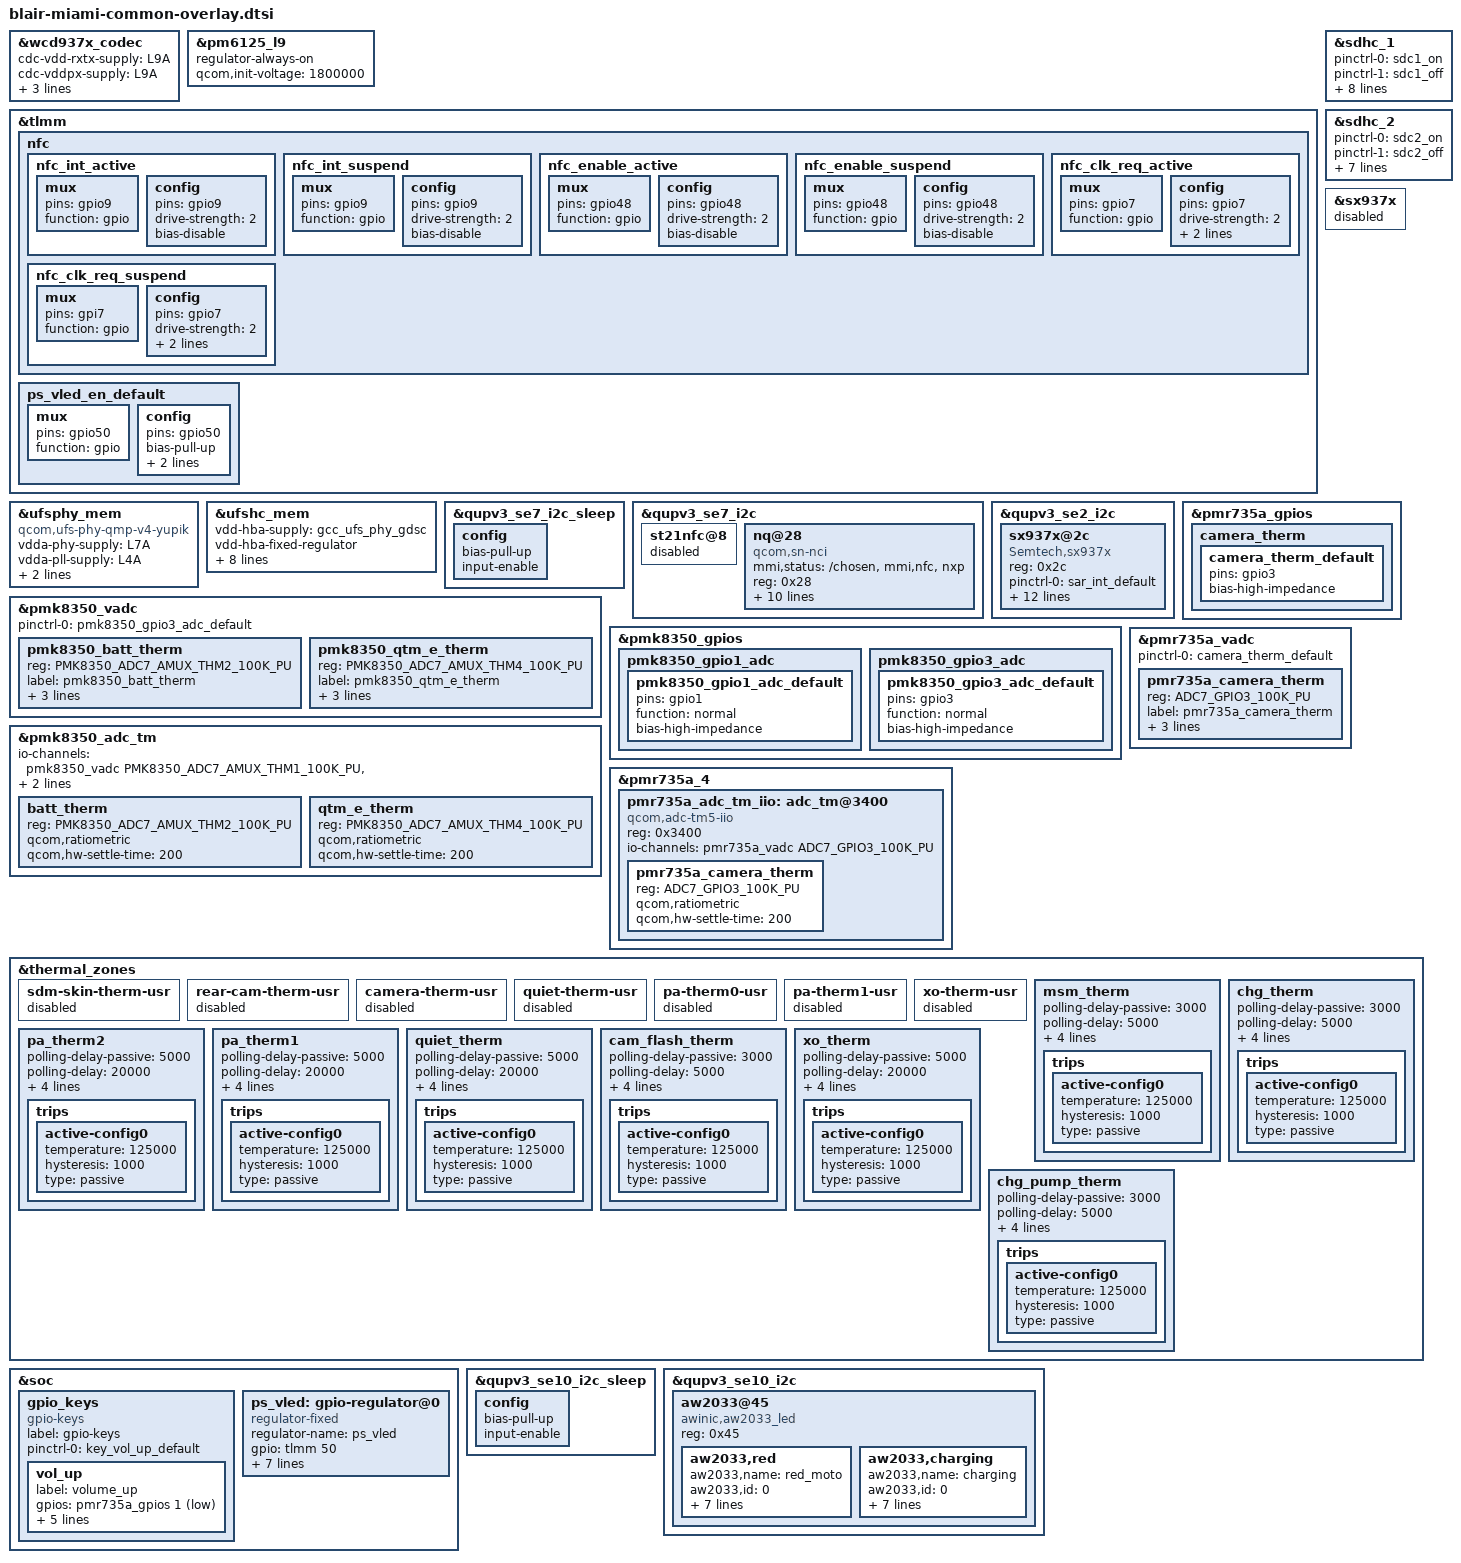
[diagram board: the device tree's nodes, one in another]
/* Copyright (c) 2021, The Linux Foundation. All rights reserved.
 *
 * This program is free software; you can redistribute it and/or modify
 * it under the terms of the GNU General Public License version 2 and
 * only version 2 as published by the Free Software Foundation.
 *
 * This program is distributed in the hope that it will be useful,
 * but WITHOUT ANY WARRANTY; without even the implied warranty of
 * MERCHANTABILITY or FITNESS FOR A PARTICULAR PURPOSE.  See the
 * GNU General Public License for more details.
 */
#include "blair-nopmi-moto-common-overlay.dtsi"

#include <dt-bindings/gpio/gpio.h>
#include <dt-bindings/input/linux-event-codes.h>
#include "holi-pmic-overlay-pm6125.dtsi"
#include "holi-thermal-overlay-pm6125.dtsi"
#include "display/holi-sde-display-mtp-pm6125.dtsi"
#include "display/blair-sde-display-mtp.dtsi"
#include "miami-fps-overlay.dtsi"
#include "miami-display.dtsi"
#include "miami-touchscreen.dtsi"
#include "camera/blair-camera-sensor-mot-miami-overlay.dtsi"
#include "miami-wl2864c.dtsi"
#include "tcpc_config.dtsi"
#include "discrete_charging_miami.dtsi"
#include "discrete-rt-pd-manger.dtsi"
#include "blair-miami-audio-overlay.dtsi"
#include "moto_therm_sys_temp.dtsi"

&wcd937x_codec {
	cdc-vdd-rxtx-supply = <&L9A>;
	cdc-vddpx-supply = <&L9A>;
	qcom,cdc-static-supplies = "cdc-vdd-rxtx",
				   "cdc-vddpx";
	/*
	 * Overriding cdc-vdd-mic-bias-supply to dummy value
	 * to avoid compilation errors as BOB is not definied
	 * for pm6125
	 */
	cdc-vdd-mic-bias-supply = <>;
};

&pm6125_l9 {
		regulator-always-on; //SAR interrupt power
		qcom,init-voltage = <1800000>;
};

&tlmm {
	nfc {
		nfc_int_active: nfc_int_active {
			/* active state */
			mux {
				/* GPIO 9: NFC Read Interrupt */
				pins = "gpio9";
				function = "gpio";
			};

			config {
				pins = "gpio9";
				drive-strength = <2>; /* 2 MA */
				bias-disable;
			};
		};

		nfc_int_suspend: nfc_int_suspend {
			/* sleep state */
			mux {
				/* GPIO 9: NFC Read Interrupt */
				pins = "gpio9";
				function = "gpio";
			};

			config {
				pins = "gpio9";
				drive-strength = <2>; /* 2 MA */
				bias-disable;
			};
		};

		nfc_enable_active: nfc_enable_active {
			mux {
				pins = "gpio48";
				function = "gpio";
			};

			config {
				pins = "gpio48";
				drive-strength = <2>; /* 2 MA */
				bias-disable;
			};
		};

		nfc_enable_suspend: nfc_enable_suspend {
			mux {
				pins = "gpio48";
				function = "gpio";
			};

			config {
				pins = "gpio48";
				drive-strength = <2>; /* 2 MA */
				bias-disable;
			};
		};


		nfc_clk_req_active: nfc_clk_req_active {
			/* active state */
			mux {
				/* GPIO 7: NFC CLK Req*/
				pins = "gpio7";
				function = "gpio";
			};

			config {
				pins = "gpio7";
				drive-strength = <2>; /* 2 MA */
				bias-disable;
				input-enable;
			};
		};

		nfc_clk_req_suspend: nfc_clk_req_suspend {
			/* sleep state */
			mux {
				/* GPIO 7: NFC CLK Req */
				pins = "gpi7";
				function = "gpio";
			};

			config {
				pins = "gpio7";
				drive-strength = <2>; /* 2 MA */
				bias-disable;
				input-enable;
			};
		};
	};
};

/* Dummy LDO reference */
&sdhc_1 {
	status = "ok";

	pinctrl-names = "default", "sleep";
	pinctrl-0 = <&sdc1_on>;
	pinctrl-1 = <&sdc1_off>;

	vdd-supply = <&L24A>;
	qcom,vdd-voltage-level = <2960000 2960000>;
	qcom,vdd-current-level = <0 570000>;

	vdd-io-supply = <&L11A>;
	qcom,vdd-io-always-on;
	qcom,vdd-io-lpm-sup;
	qcom,vdd-io-voltage-level = <1800000 1800000>;
	qcom,vdd-io-current-level = <0 325000>;
};

&sdhc_2 {
	status = "ok";

	pinctrl-names = "default", "sleep";
	pinctrl-0 = <&sdc2_on>;
	pinctrl-1 = <&sdc2_off>;

	vdd-supply = <&L22A>;
	qcom,vdd-voltage-level = <2960000 2960000>;
	qcom,vdd-current-level = <0 800000>;

	vdd-io-supply = <&L5A>;
	qcom,vdd-io-voltage-level = <1800000 2960000>;
	qcom,vdd-io-current-level = <0 22000>;

	cd-gpios = <&tlmm 94 GPIO_ACTIVE_HIGH>;
};

&ufsphy_mem {
		compatible = "qcom,ufs-phy-qmp-v4-yupik";

		vdda-phy-supply = <&L7A>;
		vdda-pll-supply = <&L4A>;
		vdda-phy-max-microamp = <85700>;
		vdda-pll-max-microamp = <18300>;

		status = "ok";
};

&ufshc_mem {
		vdd-hba-supply = <&gcc_ufs_phy_gdsc>;
		vdd-hba-fixed-regulator;

		vcc-supply = <&L24A>;
		vcc-voltage-level = <2950000 2960000>;
		vcc-max-microamp = <800000>;

		vccq2-supply = <&L11A>;
		vccq2-max-microamp = <800000>;
		vccq2-voltage-level = <1800000 1800000>;

		qcom,vddp-ref-clk-supply = <&L4A>;
		qcom,vddp-ref-clk-max-microamp = <100>;

		status = "ok";
};

&sx937x {
	status = "disabled";
};

&qupv3_se7_i2c_sleep {
    config {
        /delete-property/ bias-disable;
        bias-pull-up;
        input-enable;
    };
};

&qupv3_se7_i2c {
	status = "ok";
	#address-cells = <1>;
	#size-cells = <0>;
	st21nfc@8 {
		status = "disabled";
	};

	nq@28 {
		compatible = "qcom,sn-nci";
		mmi,status = "/chosen", "mmi,nfc", "nxp";
		reg = <0x28>;
		qcom,sn-irq = <&tlmm 9 0x00>;
		qcom,sn-ven = <&tlmm 48 0x00>;
		qcom,sn-firm = <&tlmm 8 0x00>;
		qcom,sn-clkreq = <&tlmm 7 0x00>;
		interrupt-parent = <&tlmm>;
		interrupts = <9 0>;
		interrupt-names = "nfc_irq";
		pinctrl-names = "nfc_active", "nfc_suspend";
		pinctrl-0 = <&nfc_int_active &nfc_enable_active
				&nfc_clk_req_active>;
		pinctrl-1 = <&nfc_int_suspend &nfc_enable_suspend
				&nfc_clk_req_suspend>;
	     };
};

&qupv3_se2_i2c {

	status = "ok";

	sx937x@2c {
		compatible = "Semtech,sx937x";
		reg = <0x2c>;
		pinctrl-names = "default","sleep";
		pinctrl-0 = <&sar_int_default>;
		pinctrl-1 = <&sar_int_sleep>;
		interrupt-parent = <&tlmm>;
		interrupts = <24 0x02>;
		interrupt-names = "sx937x_irq";
		Semtech,nirq-gpio = <&tlmm 24 0x02>;
                //please fix me
		cap_vdd-supply = <&pm6125_l9>;
		/*use PH4/5/6 as the reference sensor
		set it to 0xff if the ref-phases-x is not used*/
		Semtech,ref-phases-a = <5>;
		Semtech,ref-phases-b = <6>;
		Semtech,ref-phases-c = <0xff>;
		Semtech,button-flag = <0x1f>;
		Semtech,reg-num = <59>;
		Semtech,reg-init = <
			0x8024 0x7F00
			0x4004 0x70
			0x4008 0x8
			0x8020 0x32
			0x8028 0x666
			0x8034 0x466
			0x8040 0x466
			0x804C 0x466
			0x8058 0x466
			0x8064 0x466
			0x8070 0x466
			0x807C 0x85E
			0x8030 0xFFF9FD
			0x803C 0xBFF9FF
			0x8048 0xF7F9FF
			0x8054 0xFEF9FF
			0x8060 0xFFD9FF
			0x806C 0xFFF9EF
			0x8078 0xFFF97F
			0x8084 0xFFF9FF
			0x8098 0x6039
			0x80B8 0x6531
			0x80D8 0x1A1A
			0x80F8 0x4C4C
			0x8118 0x1919
			0x8138 0xFF
			0x8158 0xFF
			0x8178 0x5A40
			0x80A0 0x141400E1
			0x80C0 0xE0E00E2
			0x80E0 0x1C1C00E2
			0x8100 0x30300FA
			0x8120 0x212100E2
			0x8188 0x8000015
			0x818C 0x8000016
			0x8090 0x50DE5000
			0x80B0 0x48D45000
			0x80D0 0x3CCA5000
			0x80F0 0x3CD35000
			0x8110 0x28DD5000
			0x8130 0x54AC5000
			0x8150 0x54AC5000
			0x8170 0x54AC5000
			0x8088 0x300000
			0x80A8 0x300000
			0x80C8 0x300000
			0x80E8 0x300000
			0x8108 0x300000
			0x8128 0x3600000
			0x8148 0x3600000
			0x8168 0x300000
			0x808C 0x60200030
			0x80AC 0x60200030
			0x80CC 0x60200030
			0x80EC 0x60200030
			0x810C 0x60200030
			0x812C 0x60200030
			0x814C 0x60200030
			0x816C 0x60200030
		>;

		status = "ok";
	};
};

&pmk8350_vadc {
	pinctrl-names = "default";
	pinctrl-0 = <&pmk8350_gpio3_adc_default>;

	pmk8350_batt_therm {
		reg = <PMK8350_ADC7_AMUX_THM2_100K_PU>;
		label = "pmk8350_batt_therm";
		qcom,ratiometric;
		qcom,hw-settle-time = <200>;
		qcom,pre-scaling = <1 1>;
	};
	pmk8350_qtm_e_therm {
		reg = <PMK8350_ADC7_AMUX_THM4_100K_PU>;
		label = "pmk8350_qtm_e_therm";
		qcom,ratiometric;
		qcom,hw-settle-time = <200>;
		qcom,pre-scaling = <1 1>;
	};
};

&pmk8350_gpios {
	 pmk8350_gpio1_adc {
		pmk8350_gpio1_adc_default: pmk8350_gpio1_adc_default {
		pins = "gpio1"; /* GPIO 1 */
		function = "normal"; /* normal */
		bias-high-impedance; /* DISABLE GPIO1 for ADC*/
		};
	};

	pmk8350_gpio3_adc {
		pmk8350_gpio3_adc_default: pmk8350_gpio3_adc_default {
		pins = "gpio3"; /* GPIO 3 */
		function = "normal"; /* normal */
		bias-high-impedance; /* DISABLE GPIO3 for ADC*/
		};
	};
};

&pmk8350_adc_tm {
	io-channels = <&pmk8350_vadc PMK8350_ADC7_AMUX_THM1_100K_PU>,
			<&pmk8350_vadc PMK8350_ADC7_AMUX_THM2_100K_PU>,
			<&pmk8350_vadc PMK8350_ADC7_AMUX_THM4_100K_PU>;

	batt_therm {
		reg = <PMK8350_ADC7_AMUX_THM2_100K_PU>;
		qcom,ratiometric;
		qcom,hw-settle-time = <200>;
	};
	qtm_e_therm {
		reg = <PMK8350_ADC7_AMUX_THM4_100K_PU>;
		qcom,ratiometric;
		qcom,hw-settle-time = <200>;
	};
};

&pmr735a_gpios {
	camera_therm {
		camera_therm_default:camera_therm_default {
			pins = "gpio3";
			bias-high-impedance;
		};
	};
};

&pmr735a_vadc {
	status = "ok";

	pinctrl-names = "default";
	pinctrl-0 = <&camera_therm_default>;

	pmr735a_camera_therm {
		reg = <ADC7_GPIO3_100K_PU>;
		label = "pmr735a_camera_therm";
		qcom,ratiometric;
		qcom,hw-settle-time = <200>;
		qcom,pre-scaling = <1 1>;
	};
};

&pmr735a_4{
	pmr735a_adc_tm_iio: adc_tm@3400 {
		compatible = "qcom,adc-tm5-iio";
		reg = <0x3400>;
		#thermal-sensor-cells = <1>;
		#address-cells = <1>;
		#size-cells = <0>;
		io-channels = <&pmr735a_vadc ADC7_GPIO3_100K_PU>;

		pmr735a_camera_therm {
			reg = <ADC7_GPIO3_100K_PU>;
			qcom,ratiometric;
			qcom,hw-settle-time = <200>;
		};
	};
};

&thermal_zones {
	sdm-skin-therm-usr {
		status = "disabled";
	};
	rear-cam-therm-usr {
		status = "disabled";
	};
	camera-therm-usr {
		status = "disabled";
	};
	quiet-therm-usr {
		status = "disabled";
	};
	pa-therm0-usr {
		status = "disabled";
	};
	pa-therm1-usr {
		status = "disabled";
	};
	xo-therm-usr {
		status = "disabled";
	};
	msm_therm {
		polling-delay-passive = <3000>;
		polling-delay = <5000>;
		thermal-governor = "user_space";
		thermal-sensors = <&pm6125_adc_tm_iio ADC5_GPIO1_100K_PU>;
		wake-capable-sensor;
		trips {
			active-config0 {
				temperature = <125000>;
				hysteresis = <1000>;
				type = "passive";
			};
		};
	};

	chg_therm {
		polling-delay-passive = <3000>;
		polling-delay = <5000>;
		thermal-governor = "user_space";
		thermal-sensors = <&pm6125_adc_tm_iio ADC5_GPIO2_100K_PU>;
		wake-capable-sensor;
		trips {
			active-config0 {
				temperature = <125000>;
				hysteresis = <1000>;
				type = "passive";
			};
		};
	};

	pa_therm2 {
		polling-delay-passive = <5000>;
		polling-delay = <20000>;
		thermal-governor = "user_space";
		thermal-sensors = <&pm6125_adc_tm ADC5_GPIO4_100K_PU>;
		wake-capable-sensor;
		trips {
			active-config0 {
				temperature = <125000>;
				hysteresis = <1000>;
				type = "passive";
			};
		};
	};

	pa_therm1 {
		polling-delay-passive = <5000>;
		polling-delay = <20000>;
		thermal-governor = "user_space";
		thermal-sensors = <&pm6125_adc_tm ADC5_AMUX_THM1_100K_PU>;
		wake-capable-sensor;
		trips {
			active-config0 {
				temperature = <125000>;
				hysteresis = <1000>;
				type = "passive";
			};
		};
	};

	quiet_therm {
		polling-delay-passive = <5000>;
		polling-delay = <20000>;
		thermal-governor = "user_space";
		thermal-sensors = <&pm6125_adc_tm ADC5_AMUX_THM2_100K_PU>;
		wake-capable-sensor;
		trips {
			active-config0 {
				temperature = <125000>;
				hysteresis = <1000>;
				type = "passive";
			};
		};
	};

	cam_flash_therm {
		polling-delay-passive = <3000>;
		polling-delay = <5000>;
		thermal-governor = "user_space";
		thermal-sensors = <&pmr735a_adc_tm_iio ADC7_GPIO3_100K_PU>;
		wake-capable-sensor;
		trips {
			active-config0 {
				temperature = <125000>;
				hysteresis = <1000>;
				type = "passive";
			};
		};
	};

	xo_therm {
		polling-delay-passive = <5000>;
		polling-delay = <20000>;
		thermal-governor = "user_space";
		thermal-sensors = <&pmk8350_adc_tm PMK8350_ADC7_AMUX_THM1_100K_PU>;
		wake-capable-sensor;
		trips {
			active-config0 {
				temperature = <125000>;
				hysteresis = <1000>;
				type = "passive";
			};
		};
	};

	chg_pump_therm {
		polling-delay-passive = <3000>;
		polling-delay = <5000>;
		thermal-governor = "user_space";
		thermal-sensors = <&pmk8350_adc_tm PMK8350_ADC7_AMUX_THM4_100K_PU>;
		wake-capable-sensor;
		trips {
			active-config0 {
				temperature = <125000>;
				hysteresis = <1000>;
				type = "passive";
			};
		};
	};

};

&soc {
	gpio_keys {
		compatible = "gpio-keys";
		label = "gpio-keys";

		pinctrl-names = "default";
		pinctrl-0 = <&key_vol_up_default>;

		vol_up {
			label = "volume_up";
			gpios = <&pmr735a_gpios 1 GPIO_ACTIVE_LOW>;
			linux,input-type = <1>;
			linux,code = <KEY_VOLUMEUP>;
			gpio-key,wakeup;
			debounce-interval = <15>;
			linux,can-disable;
		};
	};
};

&tlmm {
	ps_vled_en_default: ps_vled_en_default {
		mux {
			pins = "gpio50";
			function = "gpio";
		};
		config {
			pins = "gpio50";
			bias-pull-up; /* NO PULL */
			drive-strength = <2>; /* 2 MA */
			output-high;
		};
	};
};

&soc {
	ps_vled: gpio-regulator@0 {
		compatible = "regulator-fixed";
		regulator-name = "ps_vled";
		gpio = <&tlmm 50 0>;
		regulator-min-microvolt = <3000000>;
		regulator-max-microvolt = <3000000>;
		regulator-enable-ramp-delay = <233>;
		enable-active-high;
		regulator-boot-on;
		regulator-always-on;
		pinctrl-names = "default";
		pinctrl-0 = <&ps_vled_en_default>;
	};
};

&qupv3_se10_i2c_sleep {
	config {
		/delete-property/ bias-disable;
		bias-pull-up;
		input-enable;
	};
};

&qupv3_se10_i2c {
        status = "ok";
	aw2033@45 {
		compatible = "awinic,aw2033_led";
		reg = <0x45>;

		aw2033,red {
			aw2033,name = "red_moto";
			aw2033,id = <0>;
			aw2033,imax = <1>;
			aw2033,led-current = <15>;
			aw2033,max-brightness = <255>;
			aw2033,rise-time-ms = <6>;
			aw2033,hold-time-ms = <0>;
			aw2033,fall-time-ms = <6>;
			aw2033,off-time-ms = <4>;
		};

		aw2033,charging {
			aw2033,name = "charging";
			aw2033,id = <0>;
			aw2033,imax = <1>;
			aw2033,led-current = <15>;
			aw2033,max-brightness = <255>;
			aw2033,rise-time-ms = <6>;
			aw2033,hold-time-ms = <0>;
			aw2033,fall-time-ms = <6>;
			aw2033,off-time-ms = <4>;
		};
	};
};

